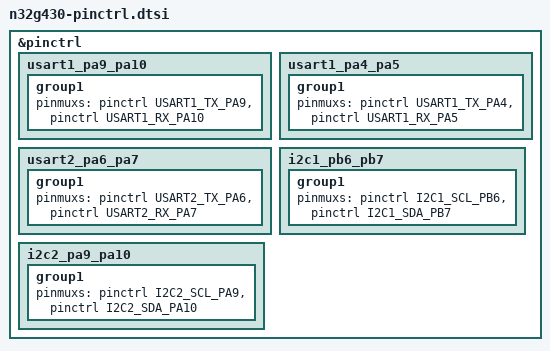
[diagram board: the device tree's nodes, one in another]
/*
 * SPDX-License-Identifier: Apache-2.0
 */

#include <zephyr/dt-bindings/pinctrl/n32g430-gpio-remap.h>
#include <zephyr/dt-bindings/pinctrl/n32g430-pinctrl.h>

/*
 pinctrl is pinmux controller, too.
*/
&pinctrl {
	usart1_pa9_pa10: usart1_pa9_pa10 {
		group1{
			pinmuxs = <&pinctrl USART1_TX_PA9>,
				<&pinctrl USART1_RX_PA10>;
		};
	};

	usart1_pa4_pa5: usart1_pa4_pa5 {
		group1{
			pinmuxs = <&pinctrl USART1_TX_PA4>,
				<&pinctrl USART1_RX_PA5>;
		};
	};

	usart2_pa6_pa7: usart2_pa6_pa7 {
		group1{
			pinmuxs = <&pinctrl USART2_TX_PA6>,
				<&pinctrl USART2_RX_PA7>;
		};
	};

	i2c1_pb6_pb7: i2c1_pb6_pb7 {
		group1{
			pinmuxs = <&pinctrl I2C1_SCL_PB6>,
				<&pinctrl I2C1_SDA_PB7>;
		};
	};

	i2c2_pa9_pa10: i2c2_pa9_pa10 {
		group1{
			pinmuxs = <&pinctrl I2C2_SCL_PA9>,
				<&pinctrl I2C2_SDA_PA10>;
		};
	};
};
